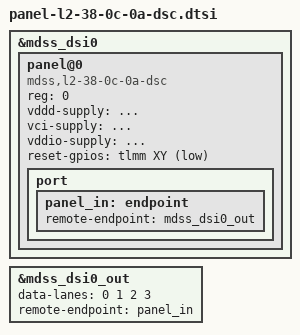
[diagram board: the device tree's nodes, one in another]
&mdss_dsi0 {
	panel@0 {
		compatible = "mdss,l2-38-0c-0a-dsc";
		reg = <0>;

		vddd-supply = <&...>;
		vci-supply = <&...>;
		vddio-supply = <&...>;
		reset-gpios = <&tlmm XY GPIO_ACTIVE_LOW>;

		port {
			panel_in: endpoint {
				remote-endpoint = <&mdss_dsi0_out>;
			};
		};
	};
};

&mdss_dsi0_out {
	data-lanes = <0 1 2 3>;
	remote-endpoint = <&panel_in>;
};
